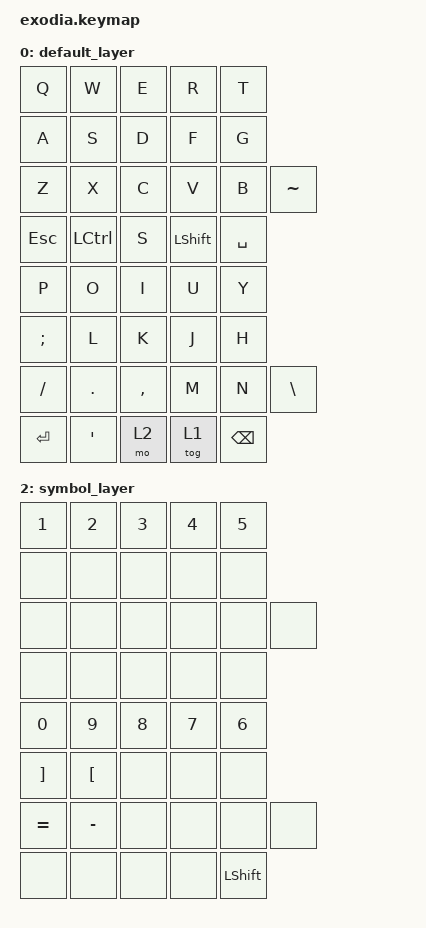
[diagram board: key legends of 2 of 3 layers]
#include <behaviors.dtsi>
#include <dt-bindings/zmk/keys.h>
#include <dt-bindings/zmk/bt.h>

/ {
    keymap {
        compatible = "zmk,keymap";

        default_layer{
            bindings = <
                &kp Q       &kp W       &kp E       &kp R           &kp T
                &kp A       &kp S       &kp D       &kp F           &kp G
                &kp Z       &kp X       &kp C       &kp V           &kp B   &kp TILDE
                &kp ESC     &kp LCTRL   &kp S       &kp LSHIFT      &kp SPACE

                &kp P       &kp O       &kp I       &kp U           &kp Y
                &kp SEMI    &kp L       &kp K       &kp J           &kp H
                &kp FSLH    &kp DOT     &kp COMMA   &kp M           &kp N   &kp BSLH
                &kp RET     &kp SQT     &mo 2       &tog 1          &kp BSPC
            >;
        };

        game_layer {
            bindings = <
                &kp N5   &kp N1   &kp N2   &kp N3   &kp N4
                &kp TAB   &kp Q   &kp W   &kp E   &kp R
                &kp LSHIFT  &kp A   &kp S   &kp D   &kp B   &kp F
                &kp LCTRL &kp TAB &kp TILDE   &kp G  &kp LALT
            >;
        };

        symbol_layer {
            bindings = <
                &kp N1      &kp N2      &kp N3      &kp N4      &kp N5
                &none       &none       &none       &none       &none
                &none       &none       &none       &none       &none   &none
                &none       &none       &none       &none       &none

                &kp N0      &kp N9      &kp N8      &kp N7      &kp N6
                &kp RBKT    &kp LBKT    &none       &none       &none
                &kp EQUAL   &kp MINUS   &none       &none       &none   &none
                &none       &none       &none       &none       &kp LSHFT
            >;
        };
    };
};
